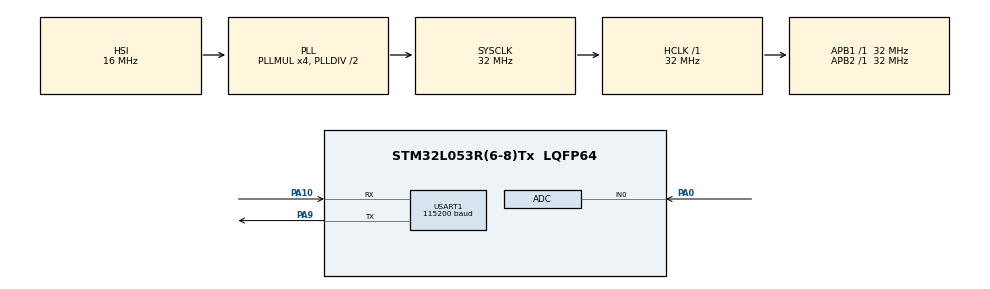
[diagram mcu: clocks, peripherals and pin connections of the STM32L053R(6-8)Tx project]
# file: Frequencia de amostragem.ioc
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ADC.ContinuousConvMode=ENABLE
ADC.DMAContinuousRequests=ENABLE
ADC.SamplingTime=ADC_SAMPLETIME_160CYCLES_5
Dma.ADC.0.Direction=DMA_PERIPH_TO_MEMORY
Dma.ADC.0.Instance=DMA1_Channel1
Dma.ADC.0.MemDataAlignment=DMA_MDATAALIGN_HALFWORD
Dma.ADC.0.MemInc=DMA_MINC_ENABLE
Dma.ADC.0.Mode=DMA_CIRCULAR
Dma.ADC.0.PeriphDataAlignment=DMA_PDATAALIGN_HALFWORD
Dma.ADC.0.PeriphInc=DMA_PINC_DISABLE
Dma.ADC.0.Priority=DMA_PRIORITY_LOW
Dma.Request0=ADC
Mcu.Family=STM32L0
Mcu.Name=STM32L053R(6-8)Tx
Mcu.Package=LQFP64
NVIC.ADC1_COMP_IRQn=true\:0\:0\:false\:false\:true\:true\:true\:true
NVIC.DMA1_Channel1_IRQn=true\:0\:0\:false\:false\:true\:false\:true\:true
PA0.Mode=IN0
PA0.Signal=ADC_IN0
PA10.Mode=Asynchronous
PA10.Signal=USART1_RX
PA9.Mode=Asynchronous
PA9.Signal=USART1_TX
ProjectManager.HeapSize=0x200
ProjectManager.StackSize=0x400
ProjectManager.TargetToolchain=STM32CubeIDE
RCC.AHBFreq_Value=32000000
RCC.APB1Freq_Value=32000000
RCC.APB1TimFreq_Value=32000000
RCC.APB2Freq_Value=32000000
RCC.APB2TimFreq_Value=32000000
RCC.HCLKFreq_Value=32000000
RCC.HSE_VALUE=8000000
RCC.HSI16_VALUE=16000000
RCC.HSI48_VALUE=48000000
RCC.HSI_VALUE=16000000
RCC.MSI_VALUE=2097000
RCC.PLLMUL=RCC_PLLMUL_4
RCC.SYSCLKFreq_VALUE=32000000
RCC.SYSCLKSource=RCC_SYSCLKSOURCE_PLLCLK
RCC.VCOOutputFreq_Value=64000000
USART1.BaudRate=115200
USART1.VirtualMode-Asynchronous=VM_ASYNC
board=NUCLEO-L053R8

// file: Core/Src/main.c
/* USER CODE BEGIN Header */
/**
  ******************************************************************************
  * @file           : main.c
  * @brief          : Main program body
  ******************************************************************************
  * @attention
  *
  * Copyright (c) 2025 STMicroelectronics.
  * All rights reserved.
  *
  * This software is licensed under terms that can be found in the LICENSE file
  * in the root directory of this software component.
  * If no LICENSE file comes with this software, it is provided AS-IS.
  *
  ******************************************************************************
  */
/* USER CODE END Header */
#include "main.h"

/* USER CODE BEGIN Includes */
#include <stdio.h>
#include <string.h>
/* USER CODE END Includes */

/* USER CODE BEGIN PD */
#define ROWS 60
/* USER CODE END PD */

ADC_HandleTypeDef hadc;
DMA_HandleTypeDef hdma_adc;

UART_HandleTypeDef huart1;

/* USER CODE BEGIN PV */
uint32_t adc[ROWS];
uint16_t adc_read;
uint8_t i, flag = 0;
char buffer[1024];
/* USER CODE END PV */

void SystemClock_Config(void);
static void MX_GPIO_Init(void);
static void MX_DMA_Init(void);
static void MX_ADC_Init(void);
static void MX_USART1_UART_Init(void);
/* USER CODE BEGIN PFP */

void FORMAT_ADC_DATA(void){
	for(int i = 0; i < ROWS; i++){
		sprintf(buffer, "%d,", (int)adc[i]);
	}
}

void HAL_ADC_ConvCpltCallback(ADC_HandleTypeDef *hadc){
	adc_read = HAL_ADC_GetValue(hadc);

	if(flag == 0){
		adc[i] = adc_read;
		i++;

		if(i > 59) {
			i = 0;
			flag = 1;
		}
	}
}
/* USER CODE END PFP */

int main(void)
{

  /* MCU Configuration--------------------------------------------------------*/

  /* Reset of all peripherals, Initializes the Flash interface and the Systick. */
  HAL_Init();

  /* Configure the system clock */
  SystemClock_Config();

  /* Initialize all configured peripherals */
  MX_GPIO_Init();
  MX_DMA_Init();
  MX_ADC_Init();
  MX_USART1_UART_Init();
  /* USER CODE BEGIN 2 */
  HAL_ADC_Start_IT(&hadc);
  /* USER CODE END 2 */

  /* Infinite loop */
  /* USER CODE BEGIN WHILE */
  while (1)
{

	  if(flag == 1){
		  HAL_UART_Transmit(&huart1, (uint8_t*)buffer, strlen(buffer), HAL_MAX_DELAY);
		  FORMAT_ADC_DATA();;
		  flag = 0;
	  }
    /* USER CODE END WHILE */

  }
}

void SystemClock_Config(void)
{
  RCC_OscInitTypeDef RCC_OscInitStruct = {0};
  RCC_ClkInitTypeDef RCC_ClkInitStruct = {0};
  RCC_PeriphCLKInitTypeDef PeriphClkInit = {0};

  /** Configure the main internal regulator output voltage
  */
  __HAL_PWR_VOLTAGESCALING_CONFIG(PWR_REGULATOR_VOLTAGE_SCALE1);

  /** Initializes the RCC Oscillators according to the specified parameters
  * in the RCC_OscInitTypeDef structure.
  */
  RCC_OscInitStruct.OscillatorType = RCC_OSCILLATORTYPE_HSI;
  RCC_OscInitStruct.HSIState = RCC_HSI_ON;
  RCC_OscInitStruct.HSICalibrationValue = RCC_HSICALIBRATION_DEFAULT;
  RCC_OscInitStruct.PLL.PLLState = RCC_PLL_ON;
  RCC_OscInitStruct.PLL.PLLSource = RCC_PLLSOURCE_HSI;
  RCC_OscInitStruct.PLL.PLLMUL = RCC_PLLMUL_4;
  RCC_OscInitStruct.PLL.PLLDIV = RCC_PLLDIV_2;
  if (HAL_RCC_OscConfig(&RCC_OscInitStruct) != HAL_OK)
  {
    Error_Handler();
  }

  /** Initializes the CPU, AHB and APB buses clocks
  */
  RCC_ClkInitStruct.ClockType = RCC_CLOCKTYPE_HCLK|RCC_CLOCKTYPE_SYSCLK
                              |RCC_CLOCKTYPE_PCLK1|RCC_CLOCKTYPE_PCLK2;
  RCC_ClkInitStruct.SYSCLKSource = RCC_SYSCLKSOURCE_PLLCLK;
  RCC_ClkInitStruct.AHBCLKDivider = RCC_SYSCLK_DIV1;
  RCC_ClkInitStruct.APB1CLKDivider = RCC_HCLK_DIV1;
  RCC_ClkInitStruct.APB2CLKDivider = RCC_HCLK_DIV1;

  if (HAL_RCC_ClockConfig(&RCC_ClkInitStruct, FLASH_LATENCY_1) != HAL_OK)
  {
    Error_Handler();
  }
  PeriphClkInit.PeriphClockSelection = RCC_PERIPHCLK_USART1;
  PeriphClkInit.Usart1ClockSelection = RCC_USART1CLKSOURCE_PCLK2;
  if (HAL_RCCEx_PeriphCLKConfig(&PeriphClkInit) != HAL_OK)
  {
    Error_Handler();
  }
}

static void MX_ADC_Init(void)
{

  ADC_ChannelConfTypeDef sConfig = {0};

  /** Configure the global features of the ADC (Clock, Resolution, Data Alignment and number of conversion)
  */
  hadc.Instance = ADC1;
  hadc.Init.OversamplingMode = DISABLE;
  hadc.Init.ClockPrescaler = ADC_CLOCK_SYNC_PCLK_DIV2;
  hadc.Init.Resolution = ADC_RESOLUTION_12B;
  hadc.Init.SamplingTime = ADC_SAMPLETIME_160CYCLES_5;
  hadc.Init.ScanConvMode = ADC_SCAN_DIRECTION_FORWARD;
  hadc.Init.DataAlign = ADC_DATAALIGN_RIGHT;
  hadc.Init.ContinuousConvMode = ENABLE;
  hadc.Init.DiscontinuousConvMode = DISABLE;
  hadc.Init.ExternalTrigConvEdge = ADC_EXTERNALTRIGCONVEDGE_NONE;
  hadc.Init.ExternalTrigConv = ADC_SOFTWARE_START;
  hadc.Init.DMAContinuousRequests = ENABLE;
  hadc.Init.EOCSelection = ADC_EOC_SINGLE_CONV;
  hadc.Init.Overrun = ADC_OVR_DATA_PRESERVED;
  hadc.Init.LowPowerAutoWait = DISABLE;
  hadc.Init.LowPowerFrequencyMode = DISABLE;
  hadc.Init.LowPowerAutoPowerOff = DISABLE;
  if (HAL_ADC_Init(&hadc) != HAL_OK)
  {
    Error_Handler();
  }

  /** Configure for the selected ADC regular channel to be converted.
  */
  sConfig.Channel = ADC_CHANNEL_0;
  sConfig.Rank = ADC_RANK_CHANNEL_NUMBER;
  if (HAL_ADC_ConfigChannel(&hadc, &sConfig) != HAL_OK)
  {
    Error_Handler();
  }

}

static void MX_USART1_UART_Init(void)
{

  huart1.Instance = USART1;
  huart1.Init.BaudRate = 115200;
  huart1.Init.WordLength = UART_WORDLENGTH_8B;
  huart1.Init.StopBits = UART_STOPBITS_1;
  huart1.Init.Parity = UART_PARITY_NONE;
  huart1.Init.Mode = UART_MODE_TX_RX;
  huart1.Init.HwFlowCtl = UART_HWCONTROL_NONE;
  huart1.Init.OverSampling = UART_OVERSAMPLING_16;
  huart1.Init.OneBitSampling = UART_ONE_BIT_SAMPLE_DISABLE;
  huart1.AdvancedInit.AdvFeatureInit = UART_ADVFEATURE_NO_INIT;
  if (HAL_UART_Init(&huart1) != HAL_OK)
  {
    Error_Handler();
  }

}

static void MX_DMA_Init(void)
{

  /* DMA controller clock enable */
  __HAL_RCC_DMA1_CLK_ENABLE();

  /* DMA interrupt init */
  /* DMA1_Channel1_IRQn interrupt configuration */
  HAL_NVIC_SetPriority(DMA1_Channel1_IRQn, 0, 0);
  HAL_NVIC_EnableIRQ(DMA1_Channel1_IRQn);

}

static void MX_GPIO_Init(void)
{

  /* GPIO Ports Clock Enable */
  __HAL_RCC_GPIOA_CLK_ENABLE();

}

void Error_Handler(void)
{
  __disable_irq();
  while (1)
  {
  }
}
